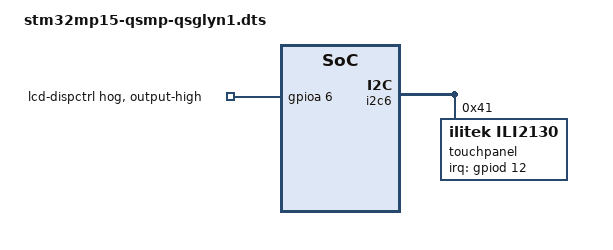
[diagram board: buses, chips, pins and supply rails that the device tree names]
// SPDX-License-Identifier: (GPL-2.0-only OR BSD-3-Clause)
/*
 * Copyright (C) 2022 Lothar Waßmann <LW@KARO-electronics.de>
 */

/dts-v1/;
/plugin/;

#include <dt-bindings/interrupt-controller/arm-gic.h>

&{/chosen} {
	overlays {
		qsmp-qsglyn1;
	};
};

&{/} {
	model = "Ka-Ro electronics GmbH QSMP-1570 module on QSGLYN1 baseboard";
};

&i2c6 {
	touchpanel@41 {
		compatible = "ilitek,ili2130";
		reg = <0x41>;
		interrupt-parent = <&gpiod>;
		interrupts = <12 IRQ_TYPE_EDGE_FALLING>;
		wakeup-source;
		status = "okay";
	};
};

&gpioa {
	lcd-dispctrl-hog {
		gpio-hog;
		gpios = <6 0>;
		output-high;
		line-name = "lcd-dispctrl";
	};
};

&spi6 {
	status = "disabled";
};
